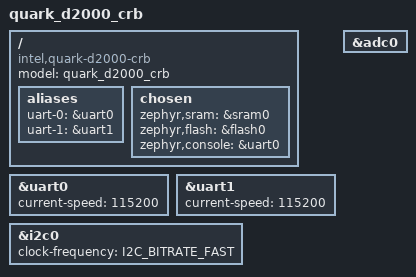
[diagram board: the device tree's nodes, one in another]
/dts-v1/;

#include <mem.h>

#define DT_FLASH_SIZE		DT_SIZE_K(32)
#define DT_SRAM_SIZE		DT_SIZE_K(8)

#include "intel_quark_d2000.dtsi"

/ {
	model = "quark_d2000_crb";
	compatible = "intel,quark-d2000-crb", "intel,quark-d2000";

	aliases {
		uart-0 = &uart0;
		uart-1 = &uart1;
	};

	chosen {
		zephyr,sram = &sram0;
		zephyr,flash = &flash0;
		zephyr,console = &uart0;
	};
};

&uart0 {
	status = "ok";
	current-speed = <115200>;
};

&uart1 {
	status = "ok";
	current-speed = <115200>;
};

&i2c0 {
	status = "ok";
	clock-frequency = <I2C_BITRATE_FAST>;
};

&adc0 {
	status = "ok";
};
